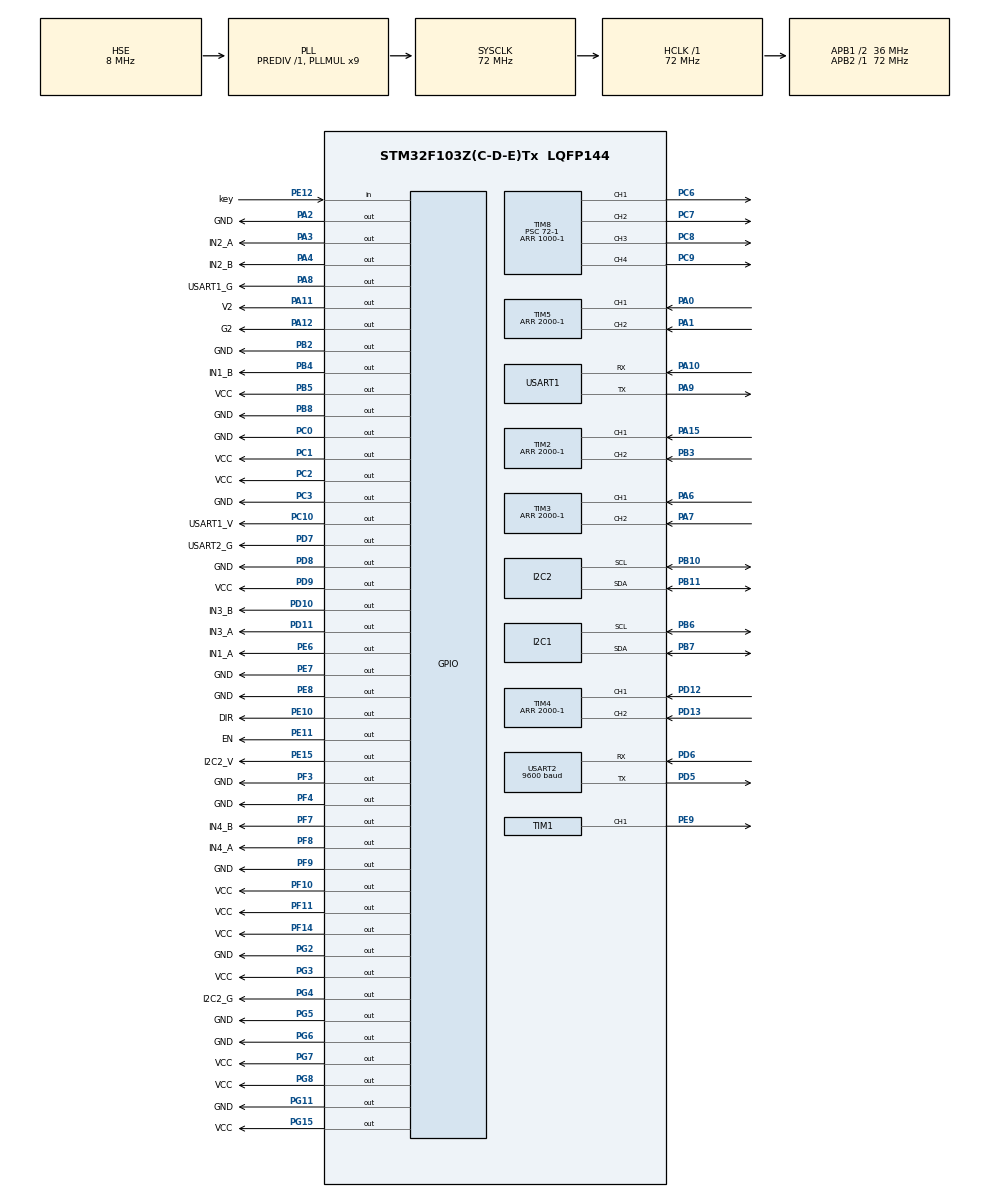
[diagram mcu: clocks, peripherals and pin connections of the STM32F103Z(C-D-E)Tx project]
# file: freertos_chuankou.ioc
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Dma.Request0=USART1_RX
Dma.Request1=USART1_TX
Dma.Request2=USART2_RX
Dma.Request3=USART2_TX
Dma.USART1_RX.0.Direction=DMA_PERIPH_TO_MEMORY
Dma.USART1_RX.0.Instance=DMA1_Channel5
Dma.USART1_RX.0.MemDataAlignment=DMA_MDATAALIGN_BYTE
Dma.USART1_RX.0.MemInc=DMA_MINC_ENABLE
Dma.USART1_RX.0.Mode=DMA_NORMAL
Dma.USART1_RX.0.PeriphDataAlignment=DMA_PDATAALIGN_BYTE
Dma.USART1_RX.0.PeriphInc=DMA_PINC_DISABLE
Dma.USART1_RX.0.Priority=DMA_PRIORITY_LOW
Dma.USART1_TX.1.Direction=DMA_MEMORY_TO_PERIPH
Dma.USART1_TX.1.Instance=DMA1_Channel4
Dma.USART1_TX.1.MemDataAlignment=DMA_MDATAALIGN_BYTE
Dma.USART1_TX.1.MemInc=DMA_MINC_ENABLE
Dma.USART1_TX.1.Mode=DMA_NORMAL
Dma.USART1_TX.1.PeriphDataAlignment=DMA_PDATAALIGN_BYTE
Dma.USART1_TX.1.PeriphInc=DMA_PINC_DISABLE
Dma.USART1_TX.1.Priority=DMA_PRIORITY_LOW
Dma.USART2_RX.2.Direction=DMA_PERIPH_TO_MEMORY
Dma.USART2_RX.2.Instance=DMA1_Channel6
Dma.USART2_RX.2.MemDataAlignment=DMA_MDATAALIGN_BYTE
Dma.USART2_RX.2.MemInc=DMA_MINC_ENABLE
Dma.USART2_RX.2.Mode=DMA_NORMAL
Dma.USART2_RX.2.PeriphDataAlignment=DMA_PDATAALIGN_BYTE
Dma.USART2_RX.2.PeriphInc=DMA_PINC_DISABLE
Dma.USART2_RX.2.Priority=DMA_PRIORITY_LOW
Dma.USART2_TX.3.Direction=DMA_MEMORY_TO_PERIPH
Dma.USART2_TX.3.Instance=DMA1_Channel7
Dma.USART2_TX.3.MemDataAlignment=DMA_MDATAALIGN_BYTE
Dma.USART2_TX.3.MemInc=DMA_MINC_ENABLE
Dma.USART2_TX.3.Mode=DMA_NORMAL
Dma.USART2_TX.3.PeriphDataAlignment=DMA_PDATAALIGN_BYTE
Dma.USART2_TX.3.PeriphInc=DMA_PINC_DISABLE
Dma.USART2_TX.3.Priority=DMA_PRIORITY_LOW
FREERTOS.BinarySemaphores01=motorSemaphores,Dynamic,NULL,Available;mpuSemaphores,Dynamic,NULL,Available;controlsSemaphores,Dynamic,NULL,Available
FREERTOS.Events01=EventGroup,Dynamic,NULL
FREERTOS.Queues01=Queue_communication,36,51,1,Dynamic,NULL,NULL
FREERTOS.Tasks01=Task_contact,40,400,APPTask_contact,Default,NULL,Dynamic,NULL,NULL;Task_go,24,128,APPTask_go,Default,NULL,Dynamic,NULL,NULL;Task_right,24,128,APPTask_right,Default,NULL,Dynamic,NULL,NULL;Task_left,24,128,APPTask_left,Default,NULL,Dynamic,NULL,NULL;Task_ut,24,128,APPTask_ut,Default,NULL,Dynamic,NULL,NULL;Task_back,24,128,APPTask_back,Default,NULL,Dynamic,NULL,NULL;Task_mpu,24,256,APPTask_mpu,Default,NULL,Dynamic,NULL,NULL;Task_controls,24,256,APPTask_controls,Default,NULL,Dynamic,NULL,NULL;Task_arm,24,256,APPTask_arm,Default,NULL,Dynamic,NULL,NULL;Task_claw,24,128,APPTask_claw,Default,NULL,Dynamic,NULL,NULL;Task_change,24,256,APPTask_change,Default,NULL,Dynamic,NULL,NULL
FREERTOS.configTOTAL_HEAP_SIZE=15000
Mcu.Family=STM32F1
Mcu.Name=STM32F103Z(C-D-E)Tx
Mcu.Package=LQFP144
NVIC.DMA1_Channel4_IRQn=true\:5\:0\:false\:false\:true\:true\:false\:true\:true
NVIC.DMA1_Channel5_IRQn=true\:5\:0\:false\:false\:true\:true\:false\:true\:true
NVIC.DMA1_Channel6_IRQn=true\:5\:0\:false\:false\:true\:true\:false\:true\:true
NVIC.DMA1_Channel7_IRQn=true\:5\:0\:false\:false\:true\:true\:false\:true\:true
NVIC.PriorityGroup=NVIC_PRIORITYGROUP_4
NVIC.TIM1_BRK_IRQn=true\:6\:0\:true\:false\:true\:true\:true\:true\:true
NVIC.TIM1_CC_IRQn=true\:6\:0\:true\:false\:true\:true\:true\:true\:true
NVIC.TIM1_TRG_COM_IRQn=true\:6\:0\:true\:false\:true\:true\:true\:true\:true
NVIC.TIM1_UP_IRQn=true\:6\:0\:true\:false\:true\:true\:true\:true\:true
NVIC.TIM2_IRQn=true\:6\:0\:true\:false\:true\:true\:true\:true\:true
NVIC.TIM3_IRQn=true\:6\:0\:true\:false\:true\:true\:true\:true\:true
NVIC.TIM4_IRQn=true\:6\:0\:true\:false\:true\:true\:true\:true\:true
NVIC.TIM5_IRQn=true\:6\:0\:true\:false\:true\:true\:true\:true\:true
NVIC.TIM6_IRQn=true\:15\:0\:false\:false\:true\:false\:false\:true\:true
NVIC.TimeBase=TIM6_IRQn
NVIC.TimeBaseIP=TIM6
NVIC.USART1_IRQn=true\:5\:0\:true\:false\:true\:true\:true\:true\:true
NVIC.USART2_IRQn=true\:5\:0\:false\:false\:true\:true\:true\:true\:true
OSC_IN.Mode=HSE-External-Oscillator
OSC_IN.Signal=RCC_OSC_IN
OSC_OUT.Mode=HSE-External-Oscillator
OSC_OUT.Signal=RCC_OSC_OUT
PA0-WKUP.GPIO_PuPd=GPIO_PULLUP
PA0-WKUP.Signal=S_TIM5_CH1
PA1.GPIO_PuPd=GPIO_PULLUP
PA1.Signal=S_TIM5_CH2
PA10.Mode=Asynchronous
PA10.Signal=USART1_RX
PA11.GPIO_Label=V2
PA11.PinState=GPIO_PIN_SET
PA11.Signal=GPIO_Output
PA12.GPIO_Label=G2
PA12.PinState=GPIO_PIN_RESET
PA12.Signal=GPIO_Output
PA13.Mode=Serial_Wire
PA13.Signal=SYS_JTMS-SWDIO
PA14.Mode=Serial_Wire
PA14.Signal=SYS_JTCK-SWCLK
PA15.GPIO_PuPd=GPIO_PULLUP
PA15.Signal=S_TIM2_CH1_ETR
PA2.GPIO_Label=GND
PA2.Signal=GPIO_Output
PA3.GPIO_Label=IN2_A
PA3.Signal=GPIO_Output
PA4.GPIO_Label=IN2_B
PA4.Signal=GPIO_Output
PA6.GPIO_PuPd=GPIO_PULLUP
PA6.Signal=S_TIM3_CH1
PA7.GPIO_PuPd=GPIO_PULLUP
PA7.Signal=S_TIM3_CH2
PA8.GPIO_Label=USART1_G
PA8.Signal=GPIO_Output
PA9.Mode=Asynchronous
PA9.Signal=USART1_TX
PB10.Mode=I2C
PB10.Signal=I2C2_SCL
PB11.Mode=I2C
PB11.Signal=I2C2_SDA
PB2.GPIO_Label=GND
PB2.Signal=GPIO_Output
PB3.GPIO_PuPd=GPIO_PULLUP
PB3.Signal=S_TIM2_CH2
PB4.GPIO_Label=IN1_B
PB4.Signal=GPIO_Output
PB5.GPIO_Label=VCC
PB5.PinState=GPIO_PIN_SET
PB5.Signal=GPIO_Output
PB6.Mode=I2C
PB6.Signal=I2C1_SCL
PB7.Mode=I2C
PB7.Signal=I2C1_SDA
PB8.GPIO_Label=GND
PB8.Signal=GPIO_Output
PC0.GPIO_Label=GND
PC0.PinState=GPIO_PIN_RESET
PC0.Signal=GPIO_Output
PC1.GPIO_Label=VCC
PC1.PinState=GPIO_PIN_SET
PC1.Signal=GPIO_Output
PC10.GPIO_Label=USART1_V
PC10.PinState=GPIO_PIN_SET
PC10.Signal=GPIO_Output
PC2.GPIO_Label=VCC
PC2.PinState=GPIO_PIN_SET
PC2.Signal=GPIO_Output
PC3.GPIO_Label=GND
PC3.Signal=GPIO_Output
PC6.Signal=S_TIM8_CH1
PC7.Signal=S_TIM8_CH2
PC8.Signal=S_TIM8_CH3
PC9.Signal=S_TIM8_CH4
PD10.GPIO_Label=IN3_B
PD10.Signal=GPIO_Output
PD11.GPIO_Label=IN3_A
PD11.Signal=GPIO_Output
PD12.GPIO_PuPd=GPIO_PULLUP
PD12.Signal=S_TIM4_CH1
PD13.GPIO_PuPd=GPIO_PULLUP
PD13.Signal=S_TIM4_CH2
PD5.Mode=Asynchronous
PD5.Signal=USART2_TX
PD6.Mode=Asynchronous
PD6.Signal=USART2_RX
PD7.GPIO_Label=USART2_G
PD7.Signal=GPIO_Output
PD8.GPIO_Label=GND
PD8.PinState=GPIO_PIN_RESET
PD8.Signal=GPIO_Output
PD9.GPIO_Label=VCC
PD9.PinState=GPIO_PIN_SET
PD9.Signal=GPIO_Output
PE10.GPIO_Label=DIR
PE10.Signal=GPIO_Output
PE11.GPIO_Label=EN
PE11.Signal=GPIO_Output
PE12.GPIO_Label=key
PE12.GPIO_PuPd=GPIO_PULLUP
PE12.Signal=GPIO_Input
PE15.GPIO_Label=I2C2_V
PE15.PinState=GPIO_PIN_SET
PE15.Signal=GPIO_Output
PE6.GPIO_Label=IN1_A
PE6.Signal=GPIO_Output
PE7.GPIO_Label=GND
PE7.PinState=GPIO_PIN_RESET
PE7.Signal=GPIO_Output
PE8.GPIO_Label=GND
PE8.PinState=GPIO_PIN_RESET
PE8.Signal=GPIO_Output
PE9.Signal=S_TIM1_CH1
PF10.GPIO_Label=VCC
PF10.PinState=GPIO_PIN_SET
PF10.Signal=GPIO_Output
PF11.GPIO_Label=VCC
PF11.PinState=GPIO_PIN_SET
PF11.Signal=GPIO_Output
PF14.GPIO_Label=VCC
PF14.PinState=GPIO_PIN_SET
PF14.Signal=GPIO_Output
PF3.GPIO_Label=GND
PF3.Signal=GPIO_Output
PF4.GPIO_Label=GND
PF4.PinState=GPIO_PIN_RESET
PF4.Signal=GPIO_Output
PF7.GPIO_Label=IN4_B
PF7.Signal=GPIO_Output
PF8.GPIO_Label=IN4_A
PF8.Signal=GPIO_Output
PF9.GPIO_Label=GND
PF9.PinState=GPIO_PIN_RESET
PF9.Signal=GPIO_Output
PG11.GPIO_Label=GND
PG11.Signal=GPIO_Output
PG15.GPIO_Label=VCC
PG15.PinState=GPIO_PIN_SET
PG15.Signal=GPIO_Output
PG2.GPIO_Label=GND
PG2.Signal=GPIO_Output
PG3.GPIO_Label=VCC
PG3.PinState=GPIO_PIN_SET
PG3.Signal=GPIO_Output
PG4.GPIO_Label=I2C2_G
PG4.Signal=GPIO_Output
PG5.GPIO_Label=GND
PG5.Signal=GPIO_Output
PG6.GPIO_Label=GND
PG6.Signal=GPIO_Output
PG7.GPIO_Label=VCC
PG7.PinState=GPIO_PIN_SET
PG7.Signal=GPIO_Output
PG8.GPIO_Label=VCC
PG8.PinState=GPIO_PIN_SET
PG8.Signal=GPIO_Output
ProjectManager.HeapSize=0x200
ProjectManager.StackSize=0x400
ProjectManager.TargetToolchain=STM32CubeIDE
RCC.AHBFreq_Value=72000000
RCC.APB1CLKDivider=RCC_HCLK_DIV2
RCC.APB1Freq_Value=36000000
RCC.APB1TimFreq_Value=72000000
RCC.APB2Freq_Value=72000000
RCC.APB2TimFreq_Value=72000000
RCC.HCLKFreq_Value=72000000
RCC.PLLMUL=RCC_PLL_MUL9
RCC.PLLSourceVirtual=RCC_PLLSOURCE_HSE
RCC.SYSCLKFreq_VALUE=72000000
RCC.SYSCLKSource=RCC_SYSCLKSOURCE_PLLCLK
RCC.USBFreq_Value=72000000
SH.S_TIM1_CH1.0=TIM1_CH1,PWM Generation1 CH1
SH.S_TIM2_CH1_ETR.0=TIM2_CH1,Encoder_Interface
SH.S_TIM2_CH2.0=TIM2_CH2,Encoder_Interface
SH.S_TIM3_CH1.0=TIM3_CH1,Encoder_Interface
SH.S_TIM3_CH2.0=TIM3_CH2,Encoder_Interface
SH.S_TIM4_CH1.0=TIM4_CH1,Encoder_Interface
SH.S_TIM4_CH2.0=TIM4_CH2,Encoder_Interface
SH.S_TIM5_CH1.0=TIM5_CH1,Encoder_Interface
SH.S_TIM5_CH2.0=TIM5_CH2,Encoder_Interface
SH.S_TIM8_CH1.0=TIM8_CH1,PWM Generation1 CH1
SH.S_TIM8_CH2.0=TIM8_CH2,PWM Generation2 CH2
SH.S_TIM8_CH3.0=TIM8_CH3,PWM Generation3 CH3
SH.S_TIM8_CH4.0=TIM8_CH4,PWM Generation4 CH4
TIM1.AutoReloadPreload=TIM_AUTORELOAD_PRELOAD_ENABLE
TIM1.Channel-PWM\ Generation1\ CH1=TIM_CHANNEL_1
TIM1.OC1Preload_PWM=DISABLE
TIM1.Period=2500-1
TIM1.Prescaler=72-1
TIM1.Pulse-PWM\ Generation1\ CH1=2500
TIM2.EncoderMode=TIM_ENCODERMODE_TI12
TIM2.IC1Filter=15
TIM2.IC2Filter=15
TIM2.Period=2000-1
TIM3.EncoderMode=TIM_ENCODERMODE_TI12
TIM3.IC1Filter=15
TIM3.IC2Filter=15
TIM3.Period=2000-1
TIM4.EncoderMode=TIM_ENCODERMODE_TI12
TIM4.IC1Filter=15
TIM4.IC2Filter=15
TIM4.Period=2000-1
TIM5.EncoderMode=TIM_ENCODERMODE_TI12
TIM5.IC1Filter=15
TIM5.IC2Filter=15
TIM5.Period=2000-1
TIM8.Channel-PWM\ Generation1\ CH1=TIM_CHANNEL_1
TIM8.Channel-PWM\ Generation2\ CH2=TIM_CHANNEL_2
TIM8.Channel-PWM\ Generation3\ CH3=TIM_CHANNEL_3
TIM8.Channel-PWM\ Generation4\ CH4=TIM_CHANNEL_4
TIM8.Period=1000-1
TIM8.Prescaler=72-1
USART1.VirtualMode=VM_ASYNC
USART2.BaudRate=9600
USART2.VirtualMode=VM_ASYNC
VP_FREERTOS_VS_CMSIS_V2.Mode=CMSIS_V2
VP_SYS_VS_tim6.Mode=TIM6
VP_TIM1_VS_ClockSourceINT.Mode=Internal
VP_TIM8_VS_ClockSourceINT.Mode=Internal
board=custom

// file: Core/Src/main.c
/* USER CODE BEGIN Header */
/**
 ******************************************************************************
 * @file           : main.c
 * @brief          : Main program body
 ******************************************************************************
 * @attention
 *
 * Copyright (c) 2024 STMicroelectronics.
 * All rights reserved.
 *
 * This software is licensed under terms that can be found in the LICENSE file
 * in the root directory of this software component.
 * If no LICENSE file comes with this software, it is provided AS-IS.
 *
 ******************************************************************************
 */
/* USER CODE END Header */
#include "main.h"
#include "cmsis_os.h"
#include "dma.h"
#include "i2c.h"
#include "tim.h"
#include "usart.h"
#include "gpio.h"

/* USER CODE BEGIN Includes */
#include "semphr.h"
/* USER CODE END Includes */

void SystemClock_Config(void);
void MX_FREERTOS_Init(void);

int main(void)
{

  /* MCU Configuration--------------------------------------------------------*/

  /* Reset of all peripherals, Initializes the Flash interface and the Systick. */
  HAL_Init();

  /* Configure the system clock */
  SystemClock_Config();

  /* Initialize all configured peripherals */
  MX_GPIO_Init();
  MX_DMA_Init();
  MX_USART1_UART_Init();
  MX_TIM1_Init();
  MX_I2C1_Init();
  MX_TIM2_Init();
  MX_TIM3_Init();
  MX_TIM4_Init();
  MX_TIM5_Init();
  MX_TIM8_Init();
  MX_I2C2_Init();
  MX_USART2_UART_Init();
  /* USER CODE BEGIN 2 */
  HAL_Delay(20);
	Motors_Init();
	extern double K2[3];
	Forward_Ctrl_Init(K2[0], K2[1], K2[2]);
	transmit_Init();
	PCA_Servo_Init();
	lift_Init();
	int ret = 0;
	do {
		ret = MPU6050_DMP_init();
		printf(".....\n");
	} while (ret);
	printf("ok\n");

//	HAL_GPIO_WritePin(GPIOB, GPIO_PIN_4, 0);
//	HAL_GPIO_WritePin(GPIOE, GPIO_PIN_6, 1);
//	TIM8->CCR1 = 500;
//
//	HAL_GPIO_WritePin(GPIOA, GPIO_PIN_3, 1);
//	HAL_GPIO_WritePin(GPIOA, GPIO_PIN_4, 0);
//	TIM8->CCR2 = 500;
//
//	HAL_GPIO_WritePin(GPIOD, GPIO_PIN_11, 1);
//	HAL_GPIO_WritePin(GPIOD, GPIO_PIN_10, 0);
//	TIM8->CCR3 = 500;
//
//	HAL_GPIO_WritePin(GPIOF, GPIO_PIN_8, 1);
//	HAL_GPIO_WritePin(GPIOF, GPIO_PIN_7, 0);
//	TIM8->CCR4 = 500;
  /* USER CODE END 2 */

  /* Init scheduler */
  osKernelInitialize();

  /* Call init function for freertos objects (in cmsis_os2.c) */
  MX_FREERTOS_Init();

  /* Start scheduler */
  osKernelStart();

  /* We should never get here as control is now taken by the scheduler */

  /* Infinite loop */
	while (1) {

	}
}

void SystemClock_Config(void)
{
  RCC_OscInitTypeDef RCC_OscInitStruct = {0};
  RCC_ClkInitTypeDef RCC_ClkInitStruct = {0};

  /** Initializes the RCC Oscillators according to the specified parameters
  * in the RCC_OscInitTypeDef structure.
  */
  RCC_OscInitStruct.OscillatorType = RCC_OSCILLATORTYPE_HSE;
  RCC_OscInitStruct.HSEState = RCC_HSE_ON;
  RCC_OscInitStruct.HSEPredivValue = RCC_HSE_PREDIV_DIV1;
  RCC_OscInitStruct.HSIState = RCC_HSI_ON;
  RCC_OscInitStruct.PLL.PLLState = RCC_PLL_ON;
  RCC_OscInitStruct.PLL.PLLSource = RCC_PLLSOURCE_HSE;
  RCC_OscInitStruct.PLL.PLLMUL = RCC_PLL_MUL9;
  if (HAL_RCC_OscConfig(&RCC_OscInitStruct) != HAL_OK)
  {
    Error_Handler();
  }

  /** Initializes the CPU, AHB and APB buses clocks
  */
  RCC_ClkInitStruct.ClockType = RCC_CLOCKTYPE_HCLK|RCC_CLOCKTYPE_SYSCLK
                              |RCC_CLOCKTYPE_PCLK1|RCC_CLOCKTYPE_PCLK2;
  RCC_ClkInitStruct.SYSCLKSource = RCC_SYSCLKSOURCE_PLLCLK;
  RCC_ClkInitStruct.AHBCLKDivider = RCC_SYSCLK_DIV1;
  RCC_ClkInitStruct.APB1CLKDivider = RCC_HCLK_DIV2;
  RCC_ClkInitStruct.APB2CLKDivider = RCC_HCLK_DIV1;

  if (HAL_RCC_ClockConfig(&RCC_ClkInitStruct, FLASH_LATENCY_2) != HAL_OK)
  {
    Error_Handler();
  }
}

/* USER CODE BEGIN 4 */
int nums_gap = 0;
/* USER CODE END 4 */

void HAL_TIM_PeriodElapsedCallback(TIM_HandleTypeDef *htim)
{
  /* USER CODE BEGIN Callback 0 */

	if (htim == GAP_TIM) {
		nums_gap++;
		if(nums_gap == 4){
			nums_gap = 0;
			extern osSemaphoreId_t mpuSemaphoresHandle;
			BaseType_t pxHigherPriorityTaskWoken1 = pdFALSE;
			if(mpuSemaphoresHandle != NULL){
				xSemaphoreGiveFromISR(mpuSemaphoresHandle,
						&pxHigherPriorityTaskWoken1);
				portYIELD_FROM_ISR(pxHigherPriorityTaskWoken1);
			}

			extern osSemaphoreId_t controlsSemaphoresHandle;
			BaseType_t pxHigherPriorityTaskWoken2 = pdFALSE;
			if(controlsSemaphoresHandle != NULL){
	//			printf("controls\n");
				xSemaphoreGiveFromISR(controlsSemaphoresHandle,
						&pxHigherPriorityTaskWoken2);
				portYIELD_FROM_ISR(pxHigherPriorityTaskWoken2);
			}
		}
		if(is_moving)
		{
			pulse_count++;
			if (pulse_count >= target_pulses) {
				// 达到目标脉冲数，停止运动
				__HAL_TIM_SET_COMPARE(&htim1, TIM_CHANNEL_1, 0);
				is_moving = 0;
				pulse_count = 0;
			}
		}
	}
  /* USER CODE END Callback 0 */
  if (htim->Instance == TIM6) {
    HAL_IncTick();
  }
}

void Error_Handler(void)
{
	__disable_irq();
	while (1) {
	}
}

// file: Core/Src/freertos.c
/* USER CODE BEGIN Header */
/**
 ******************************************************************************
 * File Name          : freertos.c
 * Description        : Code for freertos applications
 ******************************************************************************
 * @attention
 *
 * Copyright (c) 2024 STMicroelectronics.
 * All rights reserved.
 *
 * This software is licensed under terms that can be found in the LICENSE file
 * in the root directory of this software component.
 * If no LICENSE file comes with this software, it is provided AS-IS.
 *
 ******************************************************************************
 */
/* USER CODE END Header */

#include "FreeRTOS.h"
#include "task.h"
#include "main.h"
#include "cmsis_os.h"

/* USER CODE BEGIN Includes */
#include "queue.h"
#include "event_groups.h"
#include "message_buffer.h"
#include "arm6_config.h"
#include <math.h>
#include "semphr.h"

/* USER CODE END Includes */

/* USER CODE BEGIN PD */
#define STRING_GO "GO"				//指令前进
#define STRING_RIGHT "RIGHT"		//指令右转
#define STRING_LEFT "LEFT"			//指令左转
#define STRING_SERIAL "SERIAL"		//指令控制舵机
#define STRING_MOTOR "MOTOR"		//指令控制电机
#define STRING_UT "UT"				//指令超声�????????????????????????????????????????????????
#define STRING_SPEED "SPEED"		//指令控制车子速度
#define STRING_STOP "STOP"			//指令停止
#define STRING_BACK "BACK"			//指令后�??
#define STRING_ARM "ARM"			//指令机械臂控�??????????
#define STRING_CLAW "CLAW"			//指令机械爪控�??????????
#define STRING_CHANGE "CHANGE"		//指令更换桶子
#define STRING_KP "KP"
#define STRING_KI "KI"
#define STRING_KD "KD"

#define BITMASK_GO 		(0b00000001<<0)
#define BITMASK_RIGHT 	(0b00000001<<1)
#define BITMASK_LEFT 	(0b00000001<<2)
#define BITMASK_SERIAL  (0b00000001<<3)
#define BITMASK_MOTOR   (0b00000001<<4)
#define BITMASK_UT      (0b00000001<<5)
#define BITMASK_BACK    (0b00000001<<6)
#define BITMASK_ARM  	(0b00000001<<7)
#define BITMASK_CLAW	(0b00000001<<8)
#define BITMASK_CHANGE	(0b00000001<<9)

#define MSG_BUFFER_LEN 64
/* USER CODE END PD */

/* USER CODE BEGIN PM */
float position[3];
extern Motor motors[4];
extern Forward_Ctrl fctrl;
/* USER CODE END PM */

/* USER CODE BEGIN Variables */
MessageBufferHandle_t msgbuffer_SERIAL, msgbuffer_MOTOR, msgbuffer_GO, msgbuffer_CLAW, msgbuffer_CHANGE,
		msgbuffer_LEFT, msgbuffer_RIGHT, msgbuffer_UT, msgbuffer_BACK, msgbuffer_ARM;
/* USER CODE END Variables */
/* Definitions for Task_contact */
osThreadId_t Task_contactHandle;
const osThreadAttr_t Task_contact_attributes = {
  .name = "Task_contact",
  .stack_size = 400 * 4,
  .priority = (osPriority_t) osPriorityHigh,
};
/* Definitions for Task_go */
osThreadId_t Task_goHandle;
const osThreadAttr_t Task_go_attributes = {
  .name = "Task_go",
  .stack_size = 128 * 4,
  .priority = (osPriority_t) osPriorityNormal,
};
/* Definitions for Task_right */
osThreadId_t Task_rightHandle;
const osThreadAttr_t Task_right_attributes = {
  .name = "Task_right",
  .stack_size = 128 * 4,
  .priority = (osPriority_t) osPriorityNormal,
};
/* Definitions for Task_left */
osThreadId_t Task_leftHandle;
const osThreadAttr_t Task_left_attributes = {
  .name = "Task_left",
  .stack_size = 128 * 4,
  .priority = (osPriority_t) osPriorityNormal,
};
/* Definitions for Task_ut */
osThreadId_t Task_utHandle;
const osThreadAttr_t Task_ut_attributes = {
  .name = "Task_ut",
  .stack_size = 128 * 4,
  .priority = (osPriority_t) osPriorityNormal,
};
/* Definitions for Task_back */
osThreadId_t Task_backHandle;
const osThreadAttr_t Task_back_attributes = {
  .name = "Task_back",
  .stack_size = 128 * 4,
  .priority = (osPriority_t) osPriorityNormal,
};
/* Definitions for Task_mpu */
osThreadId_t Task_mpuHandle;
const osThreadAttr_t Task_mpu_attributes = {
  .name = "Task_mpu",
  .stack_size = 256 * 4,
  .priority = (osPriority_t) osPriorityNormal,
};
/* Definitions for Task_controls */
osThreadId_t Task_controlsHandle;
const osThreadAttr_t Task_controls_attributes = {
  .name = "Task_controls",
  .stack_size = 256 * 4,
  .priority = (osPriority_t) osPriorityNormal,
};
/* Definitions for Task_arm */
osThreadId_t Task_armHandle;
const osThreadAttr_t Task_arm_attributes = {
  .name = "Task_arm",
  .stack_size = 256 * 4,
  .priority = (osPriority_t) osPriorityNormal,
};
/* Definitions for Task_claw */
osThreadId_t Task_clawHandle;
const osThreadAttr_t Task_claw_attributes = {
  .name = "Task_claw",
  .stack_size = 128 * 4,
  .priority = (osPriority_t) osPriorityNormal,
};
/* Definitions for Task_change */
osThreadId_t Task_changeHandle;
const osThreadAttr_t Task_change_attributes = {
  .name = "Task_change",
  .stack_size = 256 * 4,
  .priority = (osPriority_t) osPriorityNormal,
};
/* Definitions for Queue_communication */
osMessageQueueId_t Queue_communicationHandle;
const osMessageQueueAttr_t Queue_communication_attributes = {
  .name = "Queue_communication"
};
/* Definitions for motorSemaphores */
osSemaphoreId_t motorSemaphoresHandle;
const osSemaphoreAttr_t motorSemaphores_attributes = {
  .name = "motorSemaphores"
};
/* Definitions for mpuSemaphores */
osSemaphoreId_t mpuSemaphoresHandle;
const osSemaphoreAttr_t mpuSemaphores_attributes = {
  .name = "mpuSemaphores"
};
/* Definitions for controlsSemaphores */
osSemaphoreId_t controlsSemaphoresHandle;
const osSemaphoreAttr_t controlsSemaphores_attributes = {
  .name = "controlsSemaphores"
};
/* Definitions for EventGroup */
osEventFlagsId_t EventGroupHandle;
const osEventFlagsAttr_t EventGroup_attributes = {
  .name = "EventGroup"
};

/* USER CODE BEGIN FunctionPrototypes */
int n = 0;
int count = 0;
int last = 0;
double k[3] = { 0.00, 0.00, 0.00 };
char name[3] = "pid";
/* USER CODE END FunctionPrototypes */

void APPTask_contact(void *argument);
void APPTask_go(void *argument);
void APPTask_right(void *argument);
void APPTask_left(void *argument);
void APPTask_ut(void *argument);
void APPTask_back(void *argument);
void APPTask_mpu(void *argument);
void APPTask_controls(void *argument);
void APPTask_arm(void *argument);
void APPTask_claw(void *argument);
void APPTask_change(void *argument);

void MX_FREERTOS_Init(void); /* (MISRA C 2004 rule 8.1) */

void MX_FREERTOS_Init(void) {

  /* Create the semaphores(s) */
  /* creation of motorSemaphores */
  motorSemaphoresHandle = osSemaphoreNew(1, 1, &motorSemaphores_attributes);

  /* creation of mpuSemaphores */
  mpuSemaphoresHandle = osSemaphoreNew(1, 1, &mpuSemaphores_attributes);

  /* creation of controlsSemaphores */
  controlsSemaphoresHandle = osSemaphoreNew(1, 1, &controlsSemaphores_attributes);

  /* Create the queue(s) */
  /* creation of Queue_communication */
  Queue_communicationHandle = osMessageQueueNew (36, UART_FRAME_SIZE, &Queue_communication_attributes);

  /* Create the thread(s) */
  /* creation of Task_contact */
  Task_contactHandle = osThreadNew(APPTask_contact, NULL, &Task_contact_attributes);

  /* creation of Task_go */
  Task_goHandle = osThreadNew(APPTask_go, NULL, &Task_go_attributes);

  /* creation of Task_right */
  Task_rightHandle = osThreadNew(APPTask_right, NULL, &Task_right_attributes);

  /* creation of Task_left */
  Task_leftHandle = osThreadNew(APPTask_left, NULL, &Task_left_attributes);

  /* creation of Task_ut */
  Task_utHandle = osThreadNew(APPTask_ut, NULL, &Task_ut_attributes);

  /* creation of Task_back */
  Task_backHandle = osThreadNew(APPTask_back, NULL, &Task_back_attributes);

  /* creation of Task_mpu */
  Task_mpuHandle = osThreadNew(APPTask_mpu, NULL, &Task_mpu_attributes);

  /* creation of Task_controls */
  Task_controlsHandle = osThreadNew(APPTask_controls, NULL, &Task_controls_attributes);

  /* creation of Task_arm */
  Task_armHandle = osThreadNew(APPTask_arm, NULL, &Task_arm_attributes);

  /* creation of Task_claw */
  Task_clawHandle = osThreadNew(APPTask_claw, NULL, &Task_claw_attributes);

  /* creation of Task_change */
  Task_changeHandle = osThreadNew(APPTask_change, NULL, &Task_change_attributes);

  /* USER CODE BEGIN RTOS_THREADS */
	/* add threads, ... */
	msgbuffer_GO = xMessageBufferCreate(MSG_BUFFER_LEN);
	msgbuffer_LEFT = xMessageBufferCreate(MSG_BUFFER_LEN);
	msgbuffer_SERIAL = xMessageBufferCreate(MSG_BUFFER_LEN);
	msgbuffer_MOTOR = xMessageBufferCreate(MSG_BUFFER_LEN);
	msgbuffer_RIGHT = xMessageBufferCreate(MSG_BUFFER_LEN);
	msgbuffer_UT = xMessageBufferCreate(MSG_BUFFER_LEN);
	msgbuffer_BACK = xMessageBufferCreate(MSG_BUFFER_LEN);
	msgbuffer_ARM = xMessageBufferCreate(MSG_BUFFER_LEN);
	msgbuffer_CLAW = xMessageBufferCreate(MSG_BUFFER_LEN);
	msgbuffer_CHANGE = xMessageBufferCreate(MSG_BUFFER_LEN);
  /* USER CODE END RTOS_THREADS */

  /* Create the event(s) */
  /* creation of EventGroup */
  EventGroupHandle = osEventFlagsNew(&EventGroup_attributes);

}

void APPTask_contact(void *argument)
{
  /* USER CODE BEGIN APPTask_contact */
	//定义value字符串数组来存放由上位机存放的指�????????????????????????????????????????????????????????????????????
	char value[UART_FRAME_SIZE];
	/* Infinite loop */
	for (;;) {

		//未检测到队列里的数据
		if (xQueueReceive(Queue_communicationHandle, &value, pdMS_TO_TICKS(50)) != pdTRUE){
			continue;
		}
		CommandResult res;
		res = parse_command(value);
//		printf("%s,%f,%f,%f,%f,%f,%f\n",res.command,res.params[0],res.params[1],res.params[2],res.params[3],res.params[4],res.params[5]);

		extern double K[3];
		if(strcmp(res.command, STRING_KP) == 0)
		{
			K[0] = res.params[0];
			Forward_Ctrl_Init(K[0],K[1],K[2]);
			printf("%f,%f,%f\n",K[0],K[1],K[2]);
		}

		if(strcmp(res.command, STRING_KI) == 0)
		{
			K[1] = res.params[0];
			Forward_Ctrl_Init(K[0],K[1],K[2]);
			printf("%f,%f,%f\n",K[0],K[1],K[2]);
		}

		if(strcmp(res.command, STRING_KD) == 0)
		{
			K[2] = res.params[0];
			Forward_Ctrl_Init(K[0],K[1],K[2]);
			printf("%f,%f,%f\n",K[0],K[1],K[2]);
		}

//		如果当前指令是GO
		if (strcmp(res.command, STRING_GO) == 0)
		{
			xEventGroupSetBits(EventGroupHandle, BITMASK_GO);
			xMessageBufferSend(msgbuffer_GO, &res.params[0], sizeof(double), pdMS_TO_TICKS(20));
		}

		//如果指令是RIGHT
		if (strcmp(res.command, STRING_RIGHT) == 0)
		{
			xEventGroupSetBits(EventGroupHandle, BITMASK_RIGHT);
			xMessageBufferSend(msgbuffer_RIGHT, &res.params[0], sizeof(double), pdMS_TO_TICKS(20));
		}

		//如果指令是LEFT
		if (strcmp(res.command, STRING_LEFT) == 0)
		{
			xEventGroupSetBits(EventGroupHandle, BITMASK_LEFT);
			xMessageBufferSend(msgbuffer_LEFT, &res.params[0], sizeof(double), pdMS_TO_TICKS(20));
		}

		//如果指令是BACK
		if (strcmp(res.command, STRING_BACK) == 0)
		{
			xEventGroupSetBits(EventGroupHandle, BITMASK_BACK);
			xMessageBufferSend(msgbuffer_BACK, &res.params[0], sizeof(double), pdMS_TO_TICKS(20));
		}

		//如果是指令是UT
		if (strcmp(res.command, STRING_UT) == 0)
		{
			xEventGroupSetBits(EventGroupHandle, BITMASK_UT);
			xMessageBufferSend(msgbuffer_UT, &res.params[0], sizeof(double), pdMS_TO_TICKS(20));
		}

		//如果指令是STOP
		if (strcmp(res.command, STRING_STOP) == 0)
		{
			Set_StopMode();
		}

        /* Six-axis commands cannot be interpreted as legacy ARM. */
        if (strcmp(res.command, STRING_ARM) == 0 || strcmp(res.command, "ARM6") == 0) {
            int count = strcmp(res.command, "ARM6") == 0 ? 6 : 4;
            if (res.param_count != count || (count == 6 && !ARM6_ENABLED)) continue;
            double arm_values[7] = {0};
            int valid = 1;
            for (int i = 0; i < count; ++i) {
                arm_values[i] = res.params[i];
                if (count == 6) {
                    double servo = ARM6_ZERO_DEG[i] + ARM6_DIRECTION[i] * arm_values[i];
                    if (!isfinite(servo) || servo < 0 || servo > ARM6_TRAVEL_DEG[i]) valid = 0;
                }
            }
            if (!valid) continue;
            arm_values[6] = count;
            xMessageBufferSend(msgbuffer_ARM, arm_values, sizeof(arm_values), pdMS_TO_TICKS(100));
        }

		//如果指令是CLAW
		if(strcmp(res.command, STRING_CLAW) == 0 && res.param_count == 1 && (res.params[0] == 0 || res.params[0] == 1))
		{
			xMessageBufferSend(msgbuffer_CLAW, &res.params[0], sizeof(double), pdMS_TO_TICKS(20));
		}

		//如果指令是CHANGE
		if (strcmp(res.command, STRING_CHANGE) == 0)
		{
			xEventGroupSetBits(EventGroupHandle, BITMASK_CHANGE);
			xMessageBufferSend(msgbuffer_CHANGE, &res.params[0], sizeof(double), pdMS_TO_TICKS(20));
		}
//		transmit_Init();
		vTaskDelay(pdMS_TO_TICKS(10));
	}
  /* USER CODE END APPTask_contact */
}

void APPTask_go(void *argument)
{
  /* USER CODE BEGIN APPTask_go */
	double value;
//	float coordinate[3];
//	MPU6050_DMP_Get_Date(coordinate);
	/* Infinite loop */
	for (;;) {
		xEventGroupWaitBits(EventGroupHandle, BITMASK_GO,
		pdTRUE, pdTRUE, portMAX_DELAY);
		xMessageBufferReceive(msgbuffer_GO, &value, sizeof(double), pdMS_TO_TICKS(20));

//		printf("value= %f\n",value);
		Set_StraightMode(value, TARGET);
		vTaskDelay(pdMS_TO_TICKS(10));
	}
  /* USER CODE END APPTask_go */
}

void APPTask_right(void *argument)
{
  /* USER CODE BEGIN APPTask_right */
	double value;
	/* Infinite loop */
	for (;;) {
		xEventGroupWaitBits(EventGroupHandle, BITMASK_RIGHT,
		pdTRUE, pdTRUE, portMAX_DELAY);
		xMessageBufferReceive(msgbuffer_RIGHT, &value, sizeof(double), pdMS_TO_TICKS(20));

		Set_TurnMode(value);
		vTaskDelay(pdMS_TO_TICKS(10));
	}
  /* USER CODE END APPTask_right */
}

void APPTask_left(void *argument)
{
  /* USER CODE BEGIN APPTask_left */
	double value;
	/* Infinite loop */
	for (;;) {
		xEventGroupWaitBits(EventGroupHandle, BITMASK_LEFT,
		pdTRUE, pdTRUE, portMAX_DELAY);
		xMessageBufferReceive(msgbuffer_LEFT, &value, sizeof(double), pdMS_TO_TICKS(20));

		Set_TurnMode(-value);
		vTaskDelay(pdMS_TO_TICKS(10));
	}
  /* USER CODE END APPTask_left */
}

void APPTask_ut(void *argument)
{
  /* USER CODE BEGIN APPTask_ut */
	double value;
	/* Infinite loop */
	for (;;) {
		xEventGroupWaitBits(EventGroupHandle, BITMASK_UT,
		pdFALSE, pdTRUE, portMAX_DELAY);
		xMessageBufferReceive(msgbuffer_UT, &value, sizeof(double), pdMS_TO_TICKS(20));

//		if (receive_data[0] == '1') {
//			HAL_TIM_Base_Start(&htim1);
//			HAL_TIM_IC_Start(&htim1, TIM_CHANNEL_1);
//			HAL_TIM_IC_Start_IT(&htim1, TIM_CHANNEL_2);
//			HAL_GPIO_WritePin(Trig_GPIO_Port, Trig_Pin, GPIO_PIN_SET);
//			vTaskDelay(pdMS_TO_TICKS(1));
//			HAL_GPIO_WritePin(Trig_GPIO_Port, Trig_Pin, GPIO_PIN_RESET);
//		}
//		if (receive_data[0] == '0') {
//			HAL_TIM_IC_Stop(&htim1, TIM_CHANNEL_1);
//			HAL_TIM_IC_Stop_IT(&htim1, TIM_CHANNEL_2);
//		}

//		printf("UT %c\n",receive_data[0]);
		vTaskDelay(pdMS_TO_TICKS(10));
	}
  /* USER CODE END APPTask_ut */
}

void APPTask_back(void *argument)
{
  /* USER CODE BEGIN APPTask_back */
	double value;
	/* Infinite loop */
	for (;;) {
		xEventGroupWaitBits(EventGroupHandle, BITMASK_BACK,
		pdTRUE, pdTRUE, portMAX_DELAY);
		xMessageBufferReceive(msgbuffer_BACK, &value, sizeof(double), pdMS_TO_TICKS(20));

//		printf("%f\n",value);
		Set_StraightMode(value, -TARGET);
		vTaskDelay(pdMS_TO_TICKS(10));
	}
  /* USER CODE END APPTask_back */
}

void APPTask_mpu(void *argument)
{
  /* USER CODE BEGIN APPTask_mpu */

	/* Infinite loop */
	for (;;) {
		if (xSemaphoreTake(mpuSemaphoresHandle,pdMS_TO_TICKS(10)) == pdTRUE) {
			MPU_Read();
		}
		vTaskDelay(pdMS_TO_TICKS(10));
	}
  /* USER CODE END APPTask_mpu */
}

void APPTask_controls(void *argument)
{
  /* USER CODE BEGIN APPTask_controls */
	/* Infinite loop */
	for (;;) {
		if (xSemaphoreTake(controlsSemaphoresHandle,pdMS_TO_TICKS(10)) == pdTRUE) {;
		    Forward_Control_Update(); // 更新角度�???????????????
			SpeedControl_UpdateAll(); // 更新速度�???????????????

		}
		vTaskDelay(pdMS_TO_TICKS(5));
	}
  /* USER CODE END APPTask_controls */
}

void APPTask_arm(void *argument)
{
  /* USER CODE BEGIN APPTask_arm */
    double value[7];
    for (;;) {
        if (xMessageBufferReceive(msgbuffer_ARM, value, sizeof(value), portMAX_DELAY) != sizeof(value)) continue;
        if (value[6] == 6 && ARM6_ENABLED) {
            for (int i = 0; i < 6; ++i) {
                double servo = ARM6_ZERO_DEG[i] + ARM6_DIRECTION[i] * value[i];
                set_pwm_duty_cycle(ARM6_CHANNELS[i], (float)(2.5 + 10.0 * servo / ARM6_TRAVEL_DEG[i]));
            }
        } else if (value[6] == 4) {
            PCA_Servo_270(0, value[0]);
            PCA_Servo_180(1, value[1]);
            PCA_Servo_180(2, value[2]);
            PCA_Servo_180(3, value[3]);
        }
        vTaskDelay(pdMS_TO_TICKS(10));
    }
  /* USER CODE END APPTask_arm */
}

void APPTask_claw(void *argument)
{
  /* USER CODE BEGIN APPTask_claw */
	double value;
  /* Infinite loop */
  for(;;)
  {
	  if (xMessageBufferReceive(msgbuffer_CLAW, &value, sizeof(double), portMAX_DELAY) != sizeof(double)) continue;
//	  printf("claw ok  :%d\n",(int)value);
	  if(value == 1){
		  PCA_Servo_180(5, 90);
	  }
	  else if(value == 0){
		  PCA_Servo_180(5, 0);
	  }
	  vTaskDelay(pdMS_TO_TICKS(10));
  }
  /* USER CODE END APPTask_claw */
}

void APPTask_change(void *argument)
{
  /* USER CODE BEGIN APPTask_change */
	double value;
  /* Infinite loop */
  for(;;)
  {
	  xEventGroupWaitBits(EventGroupHandle, BITMASK_CHANGE, pdTRUE, pdTRUE, portMAX_DELAY);
	  xMessageBufferReceive(msgbuffer_CHANGE, &value, sizeof(double), pdMS_TO_TICKS(20));
	  if(value == 0)		//RIGHT
	  {
		  get_out_right();
		  get_in_right();
	  }
	  else if(value == 1)	//LEFT
	  {
		  get_out_left();
		  get_in_left();
	  }
	  else if(value == 2)
	  {
		  get_in_right();
		  get_in_left();
	  }
	  vTaskDelay(pdMS_TO_TICKS(20));
  }
  /* USER CODE END APPTask_change */
}

/* USER CODE BEGIN Application */
int upEdge = 0;
int downEdge = 0;
int cha = 0;
double distance = 0;
void HAL_TIM_IC_CaptureCallback(TIM_HandleTypeDef *htim) {
//	if (htim == &htim1 && htim->Channel == HAL_TIM_ACTIVE_CHANNEL_2) {
//		upEdge = HAL_TIM_ReadCapturedValue(htim, TIM_CHANNEL_1);
//		downEdge = HAL_TIM_ReadCapturedValue(htim, TIM_CHANNEL_2);
////		printf("up= %d,down= %d\n",upEdge,downEdge);
//		cha = downEdge - upEdge;
//		if (cha < 0)
//			cha += 10000;
//		distance = cha * 0.034 / 2;
////		printf("up=%d,down=%d,cha=%d,dis=%f\n",upEdge,downEdge,cha,distance);
//		printf("%f\n", distance);
//	}
}
/* USER CODE END Application */
